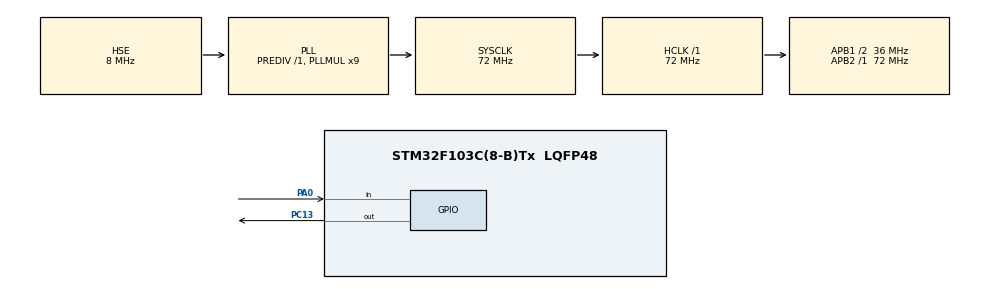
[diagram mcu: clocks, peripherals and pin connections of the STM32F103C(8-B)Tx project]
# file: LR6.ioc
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Mcu.Family=STM32F1
Mcu.Name=STM32F103C(8-B)Tx
Mcu.Package=LQFP48
NVIC.PriorityGroup=NVIC_PRIORITYGROUP_4
NVIC.TIM2_IRQn=true\:0\:0\:false\:false\:true\:true\:true\:true
PA0-WKUP.Signal=GPIO_Input
PA13.Mode=Serial_Wire
PA13.Signal=SYS_JTMS-SWDIO
PA14.Mode=Serial_Wire
PA14.Signal=SYS_JTCK-SWCLK
PC13-TAMPER-RTC.Signal=GPIO_Output
PD0-OSC_IN.Mode=HSE-External-Oscillator
PD0-OSC_IN.Signal=RCC_OSC_IN
PD1-OSC_OUT.Mode=HSE-External-Oscillator
PD1-OSC_OUT.Signal=RCC_OSC_OUT
ProjectManager.HeapSize=0x200
ProjectManager.StackSize=0x400
ProjectManager.TargetToolchain=STM32CubeIDE
RCC.AHBFreq_Value=72000000
RCC.APB1CLKDivider=RCC_HCLK_DIV2
RCC.APB1Freq_Value=36000000
RCC.APB1TimFreq_Value=72000000
RCC.APB2Freq_Value=72000000
RCC.APB2TimFreq_Value=72000000
RCC.HCLKFreq_Value=72000000
RCC.PLLMUL=RCC_PLL_MUL9
RCC.PLLSourceVirtual=RCC_PLLSOURCE_HSE
RCC.SYSCLKFreq_VALUE=72000000
RCC.SYSCLKSource=RCC_SYSCLKSOURCE_PLLCLK
RCC.USBFreq_Value=72000000
TIM2.AutoReloadPreload=TIM_AUTORELOAD_PRELOAD_ENABLE
TIM2.Period=99
TIM2.Prescaler=71
VP_TIM2_VS_ClockSourceINT.Mode=Internal
board=custom

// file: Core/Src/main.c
#include "main.h"

/* Приватні змінні ---------------------------------------------------------*/
TIM_HandleTypeDef htim2;

/* USER CODE BEGIN PV */
volatile uint8_t duty_cycle = 0; // Рівень яскравості 0-100%
uint32_t pwm_counter = 0;        // Лічильник для програмної генерації ШІМ
/* USER CODE END PV */

/* Прототипи функцій ---------------------------------------------------------*/
void SystemClock_Config(void);
static void MX_GPIO_Init(void);
static void MX_TIM2_Init(void);

/**
  * @brief Головна функція програми
  */
int main(void)
{
  /* Скидання всієї периферії, ініціалізація інтерфейсу Flash та Systick */
  HAL_Init();

  /* Налаштування системи тактування (72 МГц) */
  SystemClock_Config();

  /* Ініціалізація всіх налаштованих периферійних пристроїв */
  MX_GPIO_Init();
  MX_TIM2_Init();

  /* ЗАПУСК ТАЙМЕРА В РЕЖИМІ ПЕРЕРИВАНЬ */
  HAL_TIM_Base_Start_IT(&htim2);

  while (1)
  {
    /* Опитування кнопки на PA0 (активний низький рівень через PULL-UP) */
    if (HAL_GPIO_ReadPin(GPIOA, GPIO_PIN_0) == GPIO_PIN_RESET)
    {
      HAL_Delay(50); // Антидребезг (затримка 50 мс)
      if (HAL_GPIO_ReadPin(GPIOA, GPIO_PIN_0) == GPIO_PIN_RESET)
      {
        duty_cycle += 20; // Крок зміни яскравості 20%

        if (duty_cycle > 100)
        {
          duty_cycle = 0; // Скидання після 100%
        }

        // Очікування, поки кнопку відпустять
        while(HAL_GPIO_ReadPin(GPIOA, GPIO_PIN_0) == GPIO_PIN_RESET);
      }
    }
  }
}

/**
  * @brief Обробник переривання таймера (Callback)
  */
void HAL_TIM_PeriodElapsedCallback(TIM_HandleTypeDef *htim)
{
  if (htim->Instance == TIM2)
  {
    pwm_counter++;
    if (pwm_counter >= 100)
    {
      pwm_counter = 0;
    }

    /* Програмний ШІМ для PC13 (діод на Blue Pill) */
    /* Важливо: Reset — горить, Set — не горить */
    if (pwm_counter < duty_cycle)
    {
      HAL_GPIO_WritePin(GPIOC, GPIO_PIN_13, GPIO_PIN_RESET); // ON
    }
    else
    {
      HAL_GPIO_WritePin(GPIOC, GPIO_PIN_13, GPIO_PIN_SET);   // OFF
    }
  }
}

/**
  * @brief Налаштування TIM2 (Частота переривань 10 кГц)
  */
static void MX_TIM2_Init(void)
{
  TIM_ClockConfigTypeDef sClockSourceConfig = {0};
  TIM_MasterConfigTypeDef sMasterConfig = {0};

  htim2.Instance = TIM2;
  htim2.Init.Prescaler = 71;
  htim2.Init.CounterMode = TIM_COUNTERMODE_UP;
  htim2.Init.Period = 99;
  htim2.Init.ClockDivision = TIM_CLOCKDIVISION_DIV1;
  htim2.Init.AutoReloadPreload = TIM_AUTORELOAD_PRELOAD_ENABLE;
  if (HAL_TIM_Base_Init(&htim2) != HAL_OK)
  {
    Error_Handler();
  }
  sClockSourceConfig.ClockSource = TIM_CLOCKSOURCE_INTERNAL;
  if (HAL_TIM_ConfigClockSource(&htim2, &sClockSourceConfig) != HAL_OK)
  {
    Error_Handler();
  }
  sMasterConfig.MasterOutputTrigger = TIM_TRGO_RESET;
  sMasterConfig.MasterSlaveMode = TIM_MASTERSLAVEMODE_DISABLE; // Виправлено назву
  if (HAL_TIMEx_MasterConfigSynchronization(&htim2, &sMasterConfig) != HAL_OK)
  {
    Error_Handler();
  }
}

/**
  * @brief Налаштування GPIO (PC13 - LED, PA0 - Button)
  */
static void MX_GPIO_Init(void)
{
  GPIO_InitTypeDef GPIO_InitStruct = {0};

  __HAL_RCC_GPIOC_CLK_ENABLE();
  __HAL_RCC_GPIOA_CLK_ENABLE();

  /* Конфігурація виходу для LED (PC13) */
  HAL_GPIO_WritePin(GPIOC, GPIO_PIN_13, GPIO_PIN_SET);
  GPIO_InitStruct.Pin = GPIO_PIN_13;
  GPIO_InitStruct.Mode = GPIO_MODE_OUTPUT_PP;
  GPIO_InitStruct.Pull = GPIO_NOPULL;
  GPIO_InitStruct.Speed = GPIO_SPEED_FREQ_LOW;
  HAL_GPIO_Init(GPIOC, &GPIO_InitStruct);

  /* Конфігурація входу для Кнопки (PA0) */
  GPIO_InitStruct.Pin = GPIO_PIN_0;
  GPIO_InitStruct.Mode = GPIO_MODE_INPUT;
  GPIO_InitStruct.Pull = GPIO_PULLUP;
  HAL_GPIO_Init(GPIOA, &GPIO_InitStruct);
}

/**
  * @brief Налаштування тактування системи (72 МГц через HSE)
  */
void SystemClock_Config(void)
{
  RCC_OscInitTypeDef RCC_OscInitStruct = {0};
  RCC_ClkInitTypeDef RCC_ClkInitStruct = {0};

  RCC_OscInitStruct.OscillatorType = RCC_OSCILLATORTYPE_HSE;
  RCC_OscInitStruct.HSEState = RCC_HSE_ON;
  RCC_OscInitStruct.HSEPredivValue = RCC_HSE_PREDIV_DIV1;
  RCC_OscInitStruct.HSIState = RCC_HSI_ON;
  RCC_OscInitStruct.PLL.PLLState = RCC_PLL_ON;
  RCC_OscInitStruct.PLL.PLLSource = RCC_PLLSOURCE_HSE;
  RCC_OscInitStruct.PLL.PLLMUL = RCC_PLL_MUL9;
  if (HAL_RCC_OscConfig(&RCC_OscInitStruct) != HAL_OK)
  {
    Error_Handler();
  }

  RCC_ClkInitStruct.ClockType = RCC_CLOCKTYPE_HCLK|RCC_CLOCKTYPE_SYSCLK
                              |RCC_CLOCKTYPE_PCLK1|RCC_CLOCKTYPE_PCLK2;
  RCC_ClkInitStruct.SYSCLKSource = RCC_SYSCLKSOURCE_PLLCLK;
  RCC_ClkInitStruct.AHBCLKDivider = RCC_SYSCLK_DIV1;
  RCC_ClkInitStruct.APB1CLKDivider = RCC_HCLK_DIV2;
  RCC_ClkInitStruct.APB2CLKDivider = RCC_HCLK_DIV1;

  if (HAL_RCC_ClockConfig(&RCC_ClkInitStruct, FLASH_LATENCY_2) != HAL_OK)
  {
    Error_Handler();
  }
}

/**
  * @brief Обробник помилок
  */
void Error_Handler(void)
{
  __disable_irq();
  while (1)
  {
  }
}
